VERSION ""

NS_ :

BS_:

BU_: RVCController RVCNode // Define default node names

// Message Definitions converted from rvc-spec.yml
// NOTE: This is a partial conversion. The process should be applied to the entire rvc-spec.yml.
// NOTE: Signal byte order is assumed Intel LSB first (@1) based on YAML bit/byte definitions.
// NOTE: Default DLC is 8 bytes, common in RV-C/J1939 PGNs.
// NOTE: Factor/offset are (1,0) unless units imply scaling (requires manual interpretation). Min/Max are defaults for type.

// DM_RV (DGN = 0x1FECA) from SA=0x9D, extended
BO_ 2566834845 DM_RV: 8 RVCNode
    SG_ operating_status        :   0| 2@1+ (1,0)   [0|3]    "" RVCController
    SG_ operating_status_detail :   2| 2@1+ (1,0)   [0|3]    "" RVCController
    SG_ yellow_lamp_status      :   4| 2@1+ (1,0)   [0|3]    "" RVCController
    SG_ red_lamp_status         :   6| 2@1+ (1,0)   [0|3]    "" RVCController
    SG_ DSA                     :   8| 8@1+ (1,0)   [0|255]  "" RVCController
    SG_ SPN_MSB                 :  16| 8@1+ (1,0)   [0|255]  "" RVCController
    SG_ SPN_ISB                 :  24| 8@1+ (1,0)   [0|255]  "" RVCController
    SG_ SPN_LSB_and_FMI         :  32| 8@1+ (1,0)   [0|255]  "" RVCController

// AIR_CONDITIONER_STATUS (DGN = 0x1FFE1) from SA=0x96, extended
BO_ 2583683478 AIR_CONDITIONER_STATUS: 8 RVCNode
    SG_ instance                  :   0| 8@1+ (1,0)   [0|255] ""   RVCController
    SG_ operating_mode            :   8| 8@1+ (1,0)   [0|255] ""   RVCController
    SG_ max_fan_speed             :  16| 8@1+ (0.5,0) [0|100] "%"  RVCController
    SG_ max_ac_output_level       :  24| 8@1+ (0.5,0) [0|100] "%"  RVCController
    SG_ fan_speed                 :  32| 8@1+ (0.5,0) [0|100] "%"  RVCController
    SG_ ac_output_level           :  40| 8@1+ (0.5,0) [0|100] "%"  RVCController
    SG_ dead_band                 :  48| 8@1+ (0.1,0) [0|25]  "°C"  RVCController
    SG_ second_stage_dead_band    :  56| 8@1+ (0.1,0) [0|25]  "°C"  RVCController

// DGN 0x17F00
BO_ 2147581696 GENERAL_RESET: 8 RVCNode
	SG_ reboot : 0|2@1+ (1,0) [0|1] "" RVCController
	SG_ clear_faults : 2|2@1+ (1,0) [0|1] "" RVCController
	SG_ reset_to_default_settings : 4|2@1+ (1,0) [0|1] "" RVCController
	SG_ reset_statistics : 6|2@1+ (1,0) [0|1] "" RVCController

// DGN 0x17E00
BO_ 2147581440 TERMINAL: 8 RVCNode
	SG_ data : 0|64@1+ (1,0) [0|0] "" RVCController // Representing ASCII as raw data

// DGN 0x1FED8
BO_ 2147614424 GENERIC_CONFIGURATION_STATUS: 8 RVCNode
	SG_ manufacturer_code_LSB : 0|8@1+ (1,0) [0|255] "" RVCController
	SG_ manufacturer_code_MS_bits : 8|3@1+ (1,0) [0|7] "" RVCController
	SG_ function_instance : 11|5@1+ (1,0) [0|31] "" RVCController
	SG_ function : 16|8@1+ (1,0) [0|255] "" RVCController
	SG_ firmware_revision : 24|8@1+ (1,0) [0|255] "" RVCController
	SG_ configuration_type_LSB : 32|8@1+ (1,0) [0|255] "" RVCController
	SG_ configuration_type : 40|8@1+ (1,0) [0|255] "" RVCController
	SG_ configuration_type_MSB : 48|8@1+ (1,0) [0|255] "" RVCController
	SG_ configuration_revision : 56|8@1+ (1,0) [0|255] "" RVCController

// DGN 0x1FFFF
BO_ 2147614719 DATE_TIME_STATUS: 8 RVCNode
	SG_ year : 0|8@1+ (1,0) [0|255] "year" RVCController
	SG_ month : 8|8@1+ (1,0) [1|12] "" RVCController
	SG_ date : 16|8@1+ (1,0) [1|31] "" RVCController
	SG_ day_of_week : 24|8@1+ (1,0) [1|7] "" RVCController
	SG_ hour : 32|8@1+ (1,0) [0|23] "" RVCController
	SG_ minute : 40|8@1+ (1,0) [0|59] "" RVCController
	SG_ second : 48|8@1+ (1,0) [0|59] "" RVCController
	SG_ time_zone : 56|8@1+ (1,0) [0|255] "" RVCController

// DGN 0x1FFFE (Alias for 1FFFF)
BO_ 2147614718 SET_DATE_TIME_COMMAND: 8 RVCNode // Alias of DATE_TIME_STATUS
	SG_ year : 0|8@1+ (1,0) [0|255] "year" RVCController
	SG_ month : 8|8@1+ (1,0) [1|12] "" RVCController
	SG_ date : 16|8@1+ (1,0) [1|31] "" RVCController
	SG_ day_of_week : 24|8@1+ (1,0) [1|7] "" RVCController
	SG_ hour : 32|8@1+ (1,0) [0|23] "" RVCController
	SG_ minute : 40|8@1+ (1,0) [0|59] "" RVCController
	SG_ second : 48|8@1+ (1,0) [0|59] "" RVCController
	SG_ time_zone : 56|8@1+ (1,0) [0|255] "" RVCController

// DGN 0x1FFFD
BO_ 2147614717 DC_SOURCE_STATUS_1: 8 RVCNode
	SG_ instance : 0|8@1+ (1,0) [0|255] "" RVCController
	SG_ device_priority : 8|8@1+ (1,0) [0|255] "" RVCController
	SG_ dc_voltage : 16|16@1+ (0.01,0) [0|655.35] "V" RVCController // Assuming 0.01 scaling for V based on typical J1939/N2k
	SG_ dc_current : 32|32@1+ (0.1,0) [0|429496729.5] "A" RVCController // Assuming 0.1 scaling for A

// DGN 0x1FFFC
BO_ 2147614716 DC_SOURCE_STATUS_2: 8 RVCNode
	SG_ instance : 0|8@1+ (1,0) [0|255] "" RVCController
	SG_ device_priority : 8|8@1+ (1,0) [0|255] "" RVCController
	SG_ source_temperature : 16|16@1+ (0.03125,-273) [-273|1735] "Deg C" RVCController // Common J1939 scaling for temp
	SG_ state_of_charge : 32|8@1+ (0.4,0) [0|100] "pct" RVCController // Common J1939 scaling for %
	SG_ time_remaining : 40|16@1+ (1,0) [0|65535] "min" RVCController

// DGN 0x1FFFB
BO_ 2147614715 DC_SOURCE_STATUS_3: 8 RVCNode
	SG_ instance : 0|8@1+ (1,0) [0|255] "" RVCController
	SG_ device_priority : 8|8@1+ (1,0) [0|255] "" RVCController
	SG_ state_of_health : 16|8@1+ (0.4,0) [0|100] "pct" RVCController
	SG_ capacity_remaining : 24|16@1+ (1,0) [0|65535] "Ah" RVCController
	SG_ relative_capacity : 40|8@1+ (0.4,0) [0|100] "pct" RVCController
	SG_ ac_rms_ripple : 48|16@1+ (1,0) [0|65535] "mV" RVCController

// DGN 0x1FEC9
BO_ 2147614409 DC_SOURCE_STATUS_4: 8 RVCNode
	SG_ instance : 0|8@1+ (1,0) [0|255] "" RVCController
	SG_ device_priority : 8|8@1+ (1,0) [0|255] "" RVCController
	SG_ desired_charge_state : 16|8@1+ (1,0) [0|255] "" RVCController
	SG_ desired_dc_voltage : 24|16@1+ (0.01,0) [0|655.35] "V" RVCController
	SG_ desired_dc_current : 40|16@1+ (0.1,0) [0|6553.5] "A" RVCController
	SG_ battery_type : 56|4@1+ (1,0) [0|15] "" RVCController

// DGN 0x1FEC8
BO_ 2147614408 DC_SOURCE_STATUS_5: 8 RVCNode
	SG_ instance : 0|8@1+ (1,0) [0|255] "" RVCController
	SG_ device_priority : 8|8@1+ (1,0) [0|255] "" RVCController
	SG_ hp_dc_voltage : 16|32@1+ (0.000001,0) [0|4294.967295] "V" RVCController // High precision voltage, guess scaling
	SG_ dc_voltage_rate_of_change : 48|16@1+ (1,-32768) [-32768|32767] "mV/s" RVCController // Rate of change often signed

// DGN 0x1FEC7
BO_ 2147614407 DC_SOURCE_STATUS_6: 8 RVCNode
	SG_ instance : 0|8@1+ (1,0) [0|255] "" RVCController
	SG_ device_priority : 8|8@1+ (1,0) [0|255] "" RVCController
	SG_ high_voltage_limit_status : 16|2@1+ (1,0) [0|1] "" RVCController
	SG_ high_voltage_disconnect_status : 18|2@1+ (1,0) [0|1] "" RVCController
	SG_ low_voltage_limit_status : 20|2@1+ (1,0) [0|1] "" RVCController
	SG_ low_voltage_disconnect_status : 22|2@1+ (1,0) [0|1] "" RVCController

// DGN 0x10FFD (Alias for 1FFFD)
BO_ 2147553277 DC_SOURCE_STATUS_SPYDER: 8 RVCNode // Alias of DC_SOURCE_STATUS_1
	SG_ instance : 0|8@1+ (1,0) [0|255] "" RVCController
	SG_ device_priority : 8|8@1+ (1,0) [0|255] "" RVCController
	SG_ dc_voltage : 16|16@1+ (0.01,0) [0|655.35] "V" RVCController
	SG_ dc_current : 32|32@1+ (0.1,0) [0|429496729.5] "A" RVCController

// DGN 0x1FFFA
BO_ 2147614714 COMMUNICATION_STATUS_1: 8 RVCNode
	SG_ timer_count : 0|32@1+ (1,0) [0|4294967295] "ms" RVCController
	SG_ receive_error_count : 32|16@1+ (1,0) [0|65535] "" RVCController
	SG_ transmit_error_count : 48|16@1+ (1,0) [0|65535] "" RVCController

// DGN 0x1FFF9
BO_ 2147614713 COMMUNICATION_STATUS_2: 8 RVCNode
	SG_ transmitted_frames_count : 0|32@1+ (1,0) [0|4294967295] "" RVCController
	SG_ received_frames_count : 32|32@1+ (1,0) [0|4294967295] "" RVCController

// DGN 0x1FFF8
BO_ 2147614712 COMMUNICATION_STATUS_3: 8 RVCNode
	SG_ bus_off_error_count : 0|16@1+ (1,0) [0|65535] "" RVCController
	SG_ receive_frames_dropped_count : 16|16@1+ (1,0) [0|65535] "" RVCController
	SG_ transmit_frames_dropped_count : 32|16@1+ (1,0) [0|65535] "" RVCController

// DGN 0x1FEDA
BO_ 2147614426 DC_DIMMER_STATUS_3: 8 RVCNode
	SG_ instance : 0|8@1+ (1,0) [0|255] "" RVCController
	SG_ group : 8|8@1+ (1,0) [0|255] "" RVCController
	SG_ operating_status_brightness : 16|8@1+ (0.4,0) [0|100] "Pct" RVCController
	SG_ lock_status : 24|2@1+ (1,0) [0|3] "" RVCController // Assuming bits 0-1 for lock_status
	SG_ overcurrent_status : 26|2@1+ (1,0) [0|3] "" RVCController // Assuming bits 2-3 for overcurrent_status
	SG_ override_status : 28|2@1+ (1,0) [0|3] "" RVCController // Assuming bits 4-5 for override_status
	SG_ enable_status : 30|2@1+ (1,0) [0|3] "" RVCController // Assuming bits 6-7 for enable_status
	SG_ delay_duration : 32|8@1+ (1,0) [0|255] "" RVCController
	SG_ last_command : 40|8@1+ (1,0) [0|255] "" RVCController
	SG_ interlock_status : 48|2@1+ (1,0) [0|3] "" RVCController // Assuming bits 0-1 for interlock_status
	SG_ load_status : 50|2@1+ (1,0) [0|3] "" RVCController // Assuming bits 2-3 for load_status

// DGN 0x1FEDB
BO_ 2147614427 DC_DIMMER_COMMAND_2: 8 RVCNode
	SG_ instance : 0|8@1+ (1,0) [0|255] "" RVCController
	SG_ group : 8|8@1+ (1,0) [0|255] "" RVCController
	SG_ desired_level : 16|8@1+ (0.4,0) [0|100] "pct" RVCController
	SG_ command : 24|8@1+ (1,0) [0|255] "" RVCController
	SG_ delay_duration : 32|8@1+ (1,0) [0|255] "" RVCController
	SG_ reserved_b5 : 40|2@1+ (1,0) [0|3] "" RVCController // YAML only defines bits 0-1

// DGN 0x1FFB7
BO_ 2147614647 TANK_STATUS: 8 RVCNode
	SG_ instance : 0|8@1+ (1,0) [0|255] "" RVCController
	SG_ relative_level : 8|8@1+ (1,0) [0|255] "" RVCController
	SG_ resolution : 16|8@1+ (1,0) [0|255] "" RVCController
	SG_ absolute_level : 24|16@1+ (1,0) [0|65535] "Liter" RVCController
	SG_ tank_size : 40|16@1+ (1,0) [0|65535] "Liter" RVCController

// DGN 0x1FECA (DM_RV)
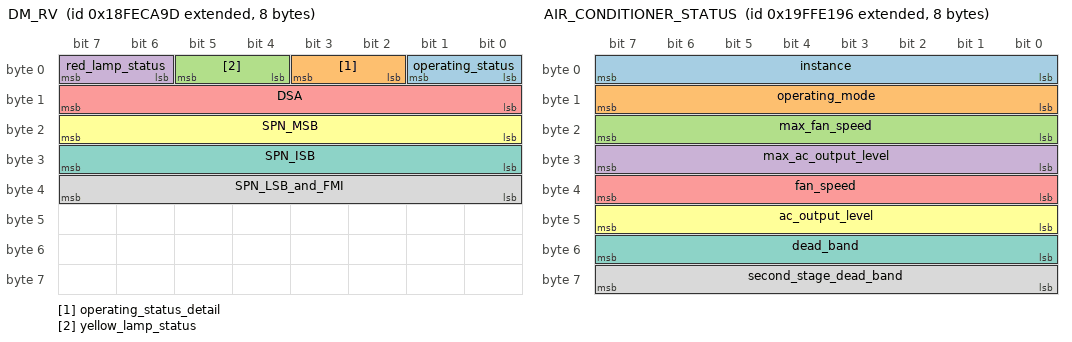
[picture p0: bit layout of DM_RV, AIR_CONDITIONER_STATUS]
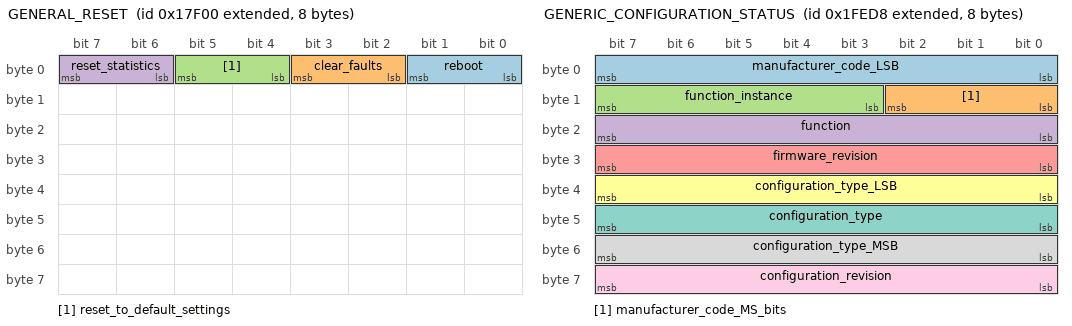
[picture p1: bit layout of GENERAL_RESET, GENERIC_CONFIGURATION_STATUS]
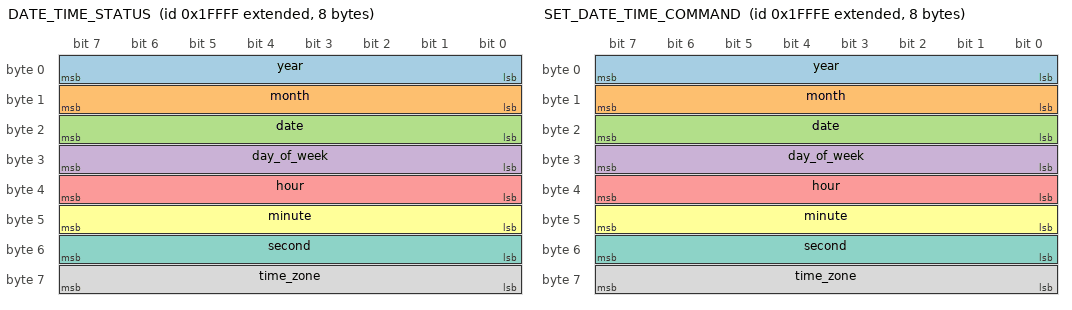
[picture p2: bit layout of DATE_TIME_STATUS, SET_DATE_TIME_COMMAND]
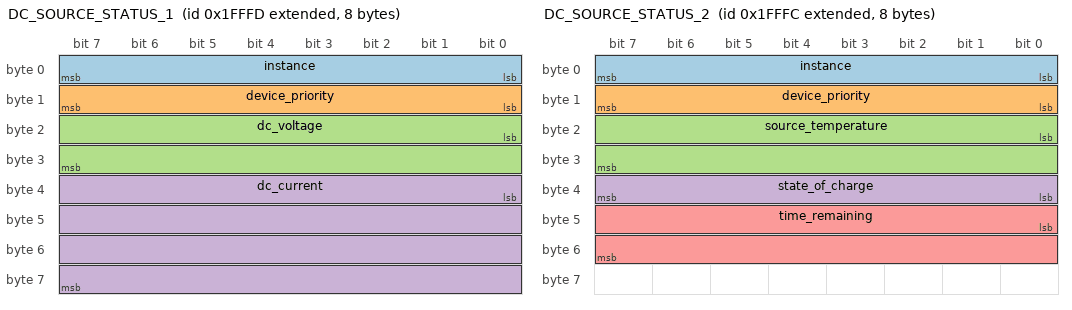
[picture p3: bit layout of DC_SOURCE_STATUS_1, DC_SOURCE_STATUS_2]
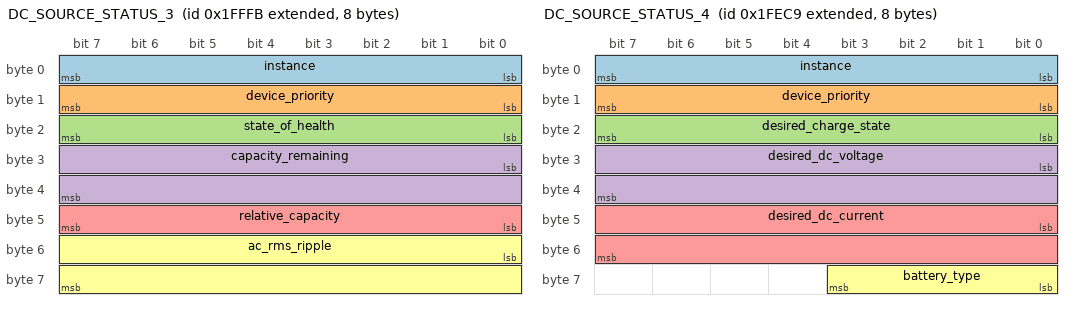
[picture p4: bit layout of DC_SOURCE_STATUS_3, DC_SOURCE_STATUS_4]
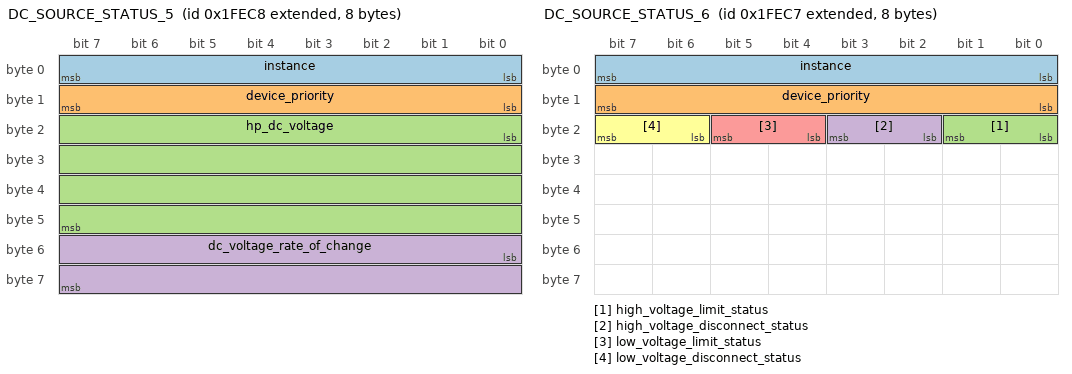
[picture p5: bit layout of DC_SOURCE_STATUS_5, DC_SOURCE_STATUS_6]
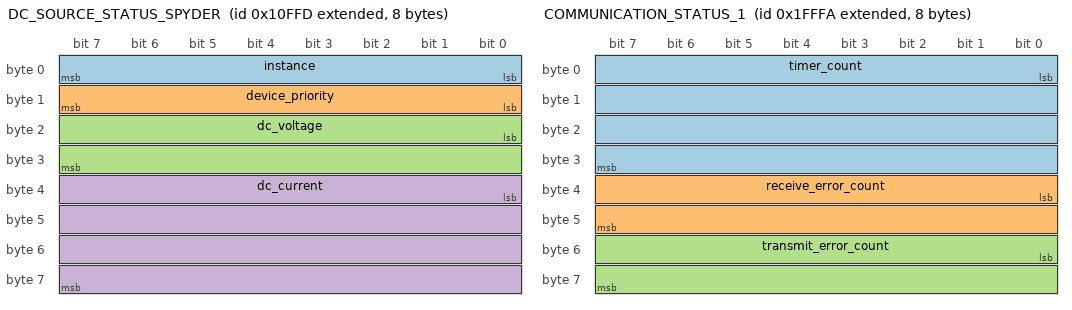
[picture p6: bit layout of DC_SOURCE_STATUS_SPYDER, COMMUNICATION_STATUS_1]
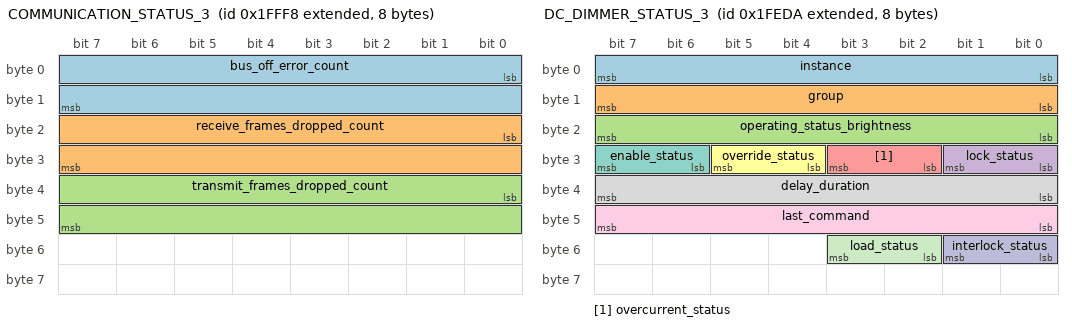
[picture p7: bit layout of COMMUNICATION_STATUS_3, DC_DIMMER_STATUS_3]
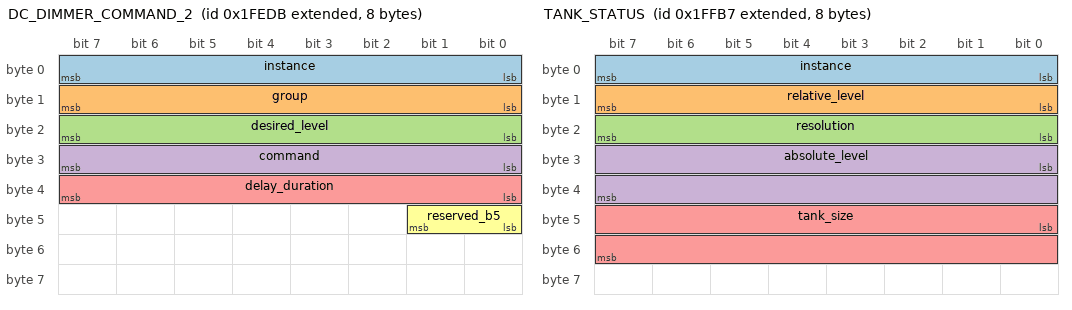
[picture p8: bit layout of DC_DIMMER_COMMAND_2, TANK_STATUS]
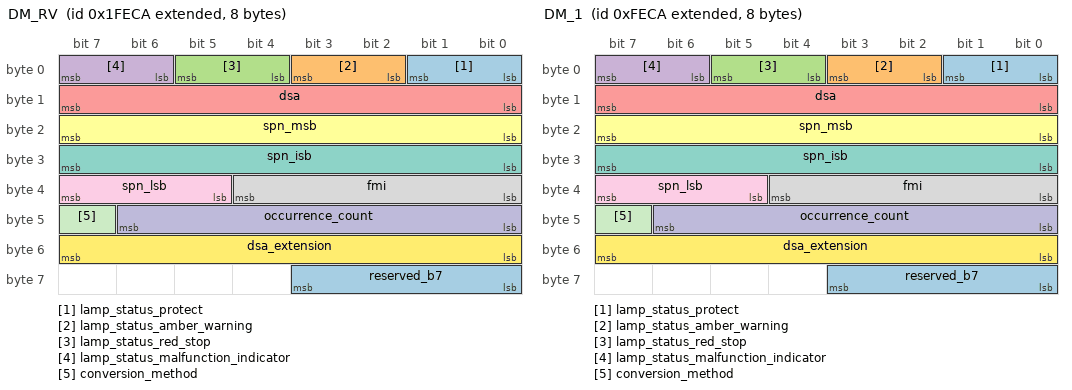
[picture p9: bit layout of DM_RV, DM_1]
BO_ 2147614410 DM_RV: 8 RVCNode
	SG_ lamp_status_protect : 0|2@1+ (1,0) [0|3] "" RVCController // Bits 0-1
	SG_ lamp_status_amber_warning : 2|2@1+ (1,0) [0|3] "" RVCController // Bits 2-3
	SG_ lamp_status_red_stop : 4|2@1+ (1,0) [0|3] "" RVCController // Bits 4-5
	SG_ lamp_status_malfunction_indicator : 6|2@1+ (1,0) [0|3] "" RVCController // Bits 6-7
	SG_ dsa : 8|8@1+ (1,0) [0|255] "" RVCController
	SG_ spn_msb : 16|8@1+ (1,0) [0|255] "" RVCController
	SG_ spn_isb : 24|8@1+ (1,0) [0|255] "" RVCController
	SG_ fmi : 32|5@1+ (1,0) [0|31] "" RVCController // Byte 4, bits 0-4
	SG_ spn_lsb : 37|3@1+ (1,0) [0|7] "" RVCController // Byte 4, bits 5-7
	SG_ occurrence_count : 40|7@1+ (1,0) [0|127] "" RVCController // Byte 5, bits 0-6
	SG_ conversion_method : 47|1@1+ (1,0) [0|1] "" RVCController // Byte 5, bit 7
	SG_ dsa_extension : 48|8@1+ (1,0) [0|255] "" RVCController
	SG_ reserved_b7 : 56|4@1+ (1,0) [0|15] "" RVCController // Byte 7, bits 0-3

// DGN 0x0FECA (DM_1 - Alias of DM_RV)
BO_ 2147548874 DM_1: 8 RVCNode
	SG_ lamp_status_protect : 0|2@1+ (1,0) [0|3] "" RVCController // Bits 0-1
	SG_ lamp_status_amber_warning : 2|2@1+ (1,0) [0|3] "" RVCController // Bits 2-3
	SG_ lamp_status_red_stop : 4|2@1+ (1,0) [0|3] "" RVCController // Bits 4-5
	SG_ lamp_status_malfunction_indicator : 6|2@1+ (1,0) [0|3] "" RVCController // Bits 6-7
	SG_ dsa : 8|8@1+ (1,0) [0|255] "" RVCController
	SG_ spn_msb : 16|8@1+ (1,0) [0|255] "" RVCController
	SG_ spn_isb : 24|8@1+ (1,0) [0|255] "" RVCController
	SG_ fmi : 32|5@1+ (1,0) [0|31] "" RVCController // Byte 4, bits 0-4
	SG_ spn_lsb : 37|3@1+ (1,0) [0|7] "" RVCController // Byte 4, bits 5-7
	SG_ occurrence_count : 40|7@1+ (1,0) [0|127] "" RVCController // Byte 5, bits 0-6
	SG_ conversion_method : 47|1@1+ (1,0) [0|1] "" RVCController // Byte 5, bit 7
	SG_ dsa_extension : 48|8@1+ (1,0) [0|255] "" RVCController
	SG_ reserved_b7 : 56|4@1+ (1,0) [0|15] "" RVCController // Byte 7, bits 0-3

// AIR_CONDITIONER_STATUS (DGN = 0x1FFE1h)
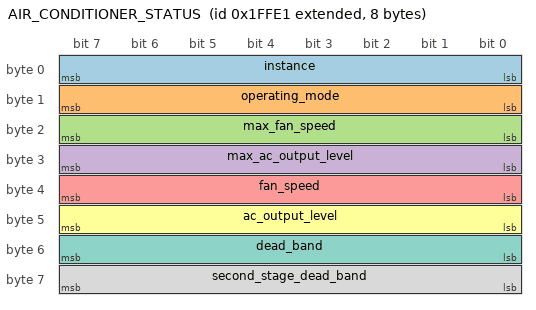
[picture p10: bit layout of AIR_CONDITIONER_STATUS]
BO_ 2147614689 AIR_CONDITIONER_STATUS: 8 RVCNode
    SG_ instance               :  0| 8@1+ (1,0)    [0|255]    ""    RVCController
    SG_ operating_mode         :  8| 8@1+ (1,0)    [0|255]    ""    RVCController
    SG_ max_fan_speed          : 16| 8@1+ (0.5,0)  [0|100]   "%"   RVCController
    SG_ max_ac_output_level    : 24| 8@1+ (0.5,0)  [0|100]   "%"   RVCController
    SG_ fan_speed              : 32| 8@1+ (0.5,0)  [0|100]   "%"   RVCController
    SG_ ac_output_level        : 40| 8@1+ (0.5,0)  [0|100]   "%"   RVCController
    SG_ dead_band              : 48| 8@1+ (0.1,0)  [0|25]   "°C"   RVCController
    SG_ second_stage_dead_band : 56| 8@1+ (0.1,0)  [0|25]   "°C"   RVCController

// DGN 0x1FF9C
BO_ 2147614620 THERMOSTAT_AMBIENT_STATUS: 8 RVCNode
	SG_ instance : 0|8@1+ (1,0) [0|255] "" RVCController
	SG_ ambient_temp : 8|16@1+ (0.03125,-273) [-273|1735] "Deg C" RVCController

// Comments for skipped Z aliases (definitions not found in YAML)
CM_ "Messages aliasing Z0000 (e.g., 1FFDF, 1FFD7, 1FFCA, 1FEBB) were skipped as Z0000 definition is missing.";
CM_ "Messages aliasing Z0001 (e.g., 1FFDE, 1FFD6, 1FFC9, 1FEBA) were skipped as Z0001 definition is missing.";
CM_ "Messages aliasing Z0002 (e.g., 1FFDD, 1FFD5, 1FFC8, 1FEB9) were skipped as Z0002 definition is missing.";
CM_ "Messages aliasing Z0003 (e.g., 1FF94, 1FF8F, 1FF8A, 1FEB8) were skipped as Z0003 definition is missing.";
CM_ "Messages aliasing Z0004 (e.g., 1FF8E, 1FF8C, 1FF89, 1FF87, 1FEB7, 1FEB5) were skipped as Z0004 definition is missing.";
CM_ "Messages aliasing Z0005 (e.g., 1FF8D, 1FF8B, 1FF88, 1FF86, 1FEB6, 1FEB4) were skipped as Z0005 definition is missing.";

// Value Table Definitions (corresponding to converted messages)

VAL_ 2147581696 reboot 1 "Reboot" 0 "no_action" ;
VAL_ 2147581696 clear_faults 1 "clear_faults" 0 "no_action" ;
VAL_ 2147581696 reset_to_default_settings 1 "reset_to_default_settings" 0 "no_action" ;
VAL_ 2147581696 reset_statistics 1 "reset_statistics" 0 "no_action" ;

VAL_ 2147614719 day_of_week 7 "Saturday" 6 "Friday" 5 "Thursday" 4 "Wednesday" 3 "Tuesday" 2 "Monday" 1 "Sunday" ;
VAL_ 2147614719 time_zone 22 "Central_European_Summer_Time" 8 "Pacific_Standard_Time" 7 "Pacific_Daylight_Time" 5 "Eastern_Standard_Time" 4 "Eastern_Daylight_Time" 0 "Greenwich_Mean_Time" ;
// VAL for alias 1FFFE (131070)
VAL_ 2147614718 day_of_week 7 "Saturday" 6 "Friday" 5 "Thursday" 4 "Wednesday" 3 "Tuesday" 2 "Monday" 1 "Sunday" ;
VAL_ 2147614718 time_zone 22 "Central_European_Summer_Time" 8 "Pacific_Standard_Time" 7 "Pacific_Daylight_Time" 5 "Eastern_Standard_Time" 4 "Eastern_Daylight_Time" 0 "Greenwich_Mean_Time" ;

VAL_ 2147614717 instance 3 "secondary_house_battery_bank" 2 "chassis_start_battery" 1 "main_house_battery_bank" 0 "invalid" ;
VAL_ 2147614717 device_priority 120 "battery_soc_device" 100 "inverter_charger" 80 "charger" 60 "inverter" 40 "voltmeter_ammeter" 20 "voltmeter" ;
// VAL for alias 10FFD (69629)
VAL_ 2147553277 instance 3 "secondary_house_battery_bank" 2 "chassis_start_battery" 1 "main_house_battery_bank" 0 "invalid" ;
VAL_ 2147553277 device_priority 120 "battery_soc_device" 100 "inverter_charger" 80 "charger" 60 "inverter" 40 "voltmeter_ammeter" 20 "voltmeter" ;

VAL_ 2147614716 instance 3 "secondary_house_battery_bank" 2 "chassis_start_battery" 1 "main_house_battery_bank" 0 "invalid" ;
VAL_ 2147614716 device_priority 120 "battery_soc_device" 100 "inverter_Charger" 80 "charger" 60 "inverter" 40 "voltmeter_ammeter" 20 "voltmeter" ; // Note: "inverter Charger" vs "inverter charger" in 1FFFD

VAL_ 2147614715 instance 3 "secondary_house_battery_bank" 2 "chassis_start_battery" 1 "main_house_battery_bank" 0 "invalid" ;
VAL_ 2147614715 device_priority 120 "battery_soc_device" 100 "inverter_charger" 80 "charger" 60 "inverter" 40 "voltmeter_ammeter" 20 "voltmeter" ;

VAL_ 2147614409 instance 3 "secondary_house_battery_bank" 2 "chassis_start_battery" 1 "main_house_battery_bank" 0 "invalid" ;
VAL_ 2147614409 device_priority 120 "battery_soc_device" 100 "inverter_charger" 80 "charger" 60 "inverter" 40 "voltmeter_ammeter" 20 "voltmeter" ;
VAL_ 2147614409 desired_charge_state 7 "constant_voltage_current" 6 "float" 5 "equalize" 4 "overcharge" 3 "absorbtion" 2 "bulk" 1 "do_not_charge" 0 "undefined" ; // Note typo "absorbtion" in source
VAL_ 2147614409 battery_type 3 "lithium_iron_phosphate" 2 "agm" 1 "gel" 0 "flooded" ;

VAL_ 2147614408 instance 3 "secondary_house_battery_bank" 2 "chassis_start_battery" 1 "main_house_battery_bank" 0 "invalid" ;
VAL_ 2147614408 device_priority 120 "battery_soc_device" 100 "inverter_charger" 80 "charger" 60 "inverter" 40 "voltmeter_ammeter" 20 "voltmeter" ;

VAL_ 2147614407 instance 3 "secondary_house_battery_bank" 2 "chassis_start_battery" 1 "main_house_battery_bank" 0 "invalid" ;
VAL_ 2147614407 device_priority 120 "battery_soc_device" 100 "inverter_charger" 80 "charger" 60 "inverter" 40 "voltmeter_ammeter" 20 "voltmeter" ;
VAL_ 2147614407 high_voltage_limit_status 1 "limit_reached" 0 "not_reached" ;
VAL_ 2147614407 high_voltage_disconnect_status 1 "charge_bus_disconnected" 0 "connected" ;
VAL_ 2147614407 low_voltage_limit_status 1 "limit_reached" 0 "not_reached" ;
VAL_ 2147614407 low_voltage_disconnect_status 1 "charge_bus_disconnected" 0 "connected" ;

VAL_ 2147614689 operating_mode 1 "manual" 0 "automatic" ;

// ... Rest of the value tables need to be converted ...
